# HC32K118 register map
File version: 1.0
CPU: CM0+ r0p1, little endian, no MPU, no FPU, 2 interrupt priority bits
Registers are 32-bit, read-write, reset 0x0 unless marked. A register's access mark holds for its fields unless they carry their own. Offsets are from the block's base; [hi:lo] are bit positions; {n}, {i} and the like mark numbered series; 'fields as' and 'values as' point back to an identical list.

## GPIO
Base 0x40013800
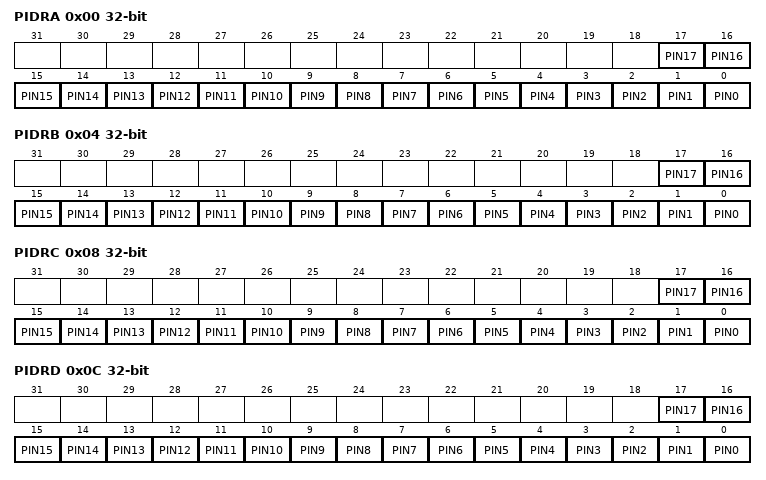
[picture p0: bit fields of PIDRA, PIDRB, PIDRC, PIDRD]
0x00 PIDRA ro (reset mask 0x3CFF)
  [n] PIN{n} (n=0..17)
0x04 PIDRB ro (reset mask 0x3CFF)
  [n] PIN{n} (n=0..17)
0x08 PIDRC ro (reset mask 0x3CFF)
  [n] PIN{n} (n=0..17)
0x0C PIDRD ro (reset mask 0x3CFF)
  [n] PIN{n} (n=0..17)
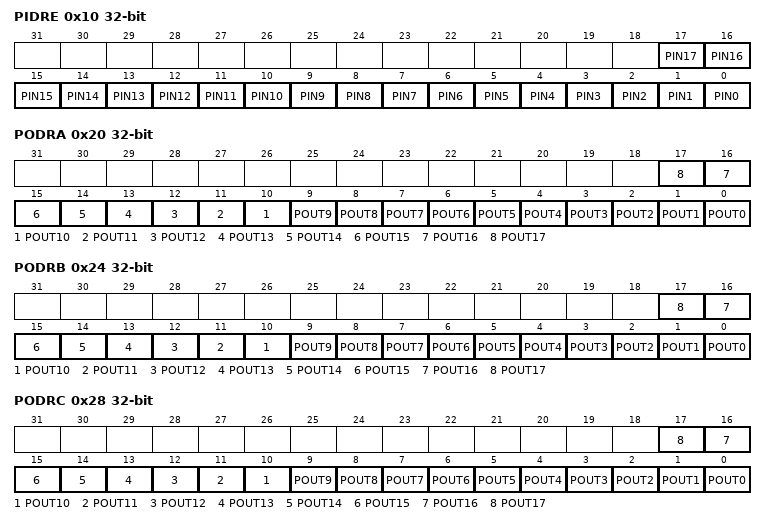
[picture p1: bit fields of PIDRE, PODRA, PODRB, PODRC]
0x10 PIDRE ro (reset mask 0x3CFF)
  [n] PIN{n} (n=0..17)
0x20 PODRA (reset mask 0x3CFF)
  [n] POUT{n} (n=0..17)
0x24 PODRB (reset mask 0x3CFF)
  [n] POUT{n} (n=0..17)
0x28 PODRC (reset mask 0x3CFF)
  [n] POUT{n} (n=0..17)
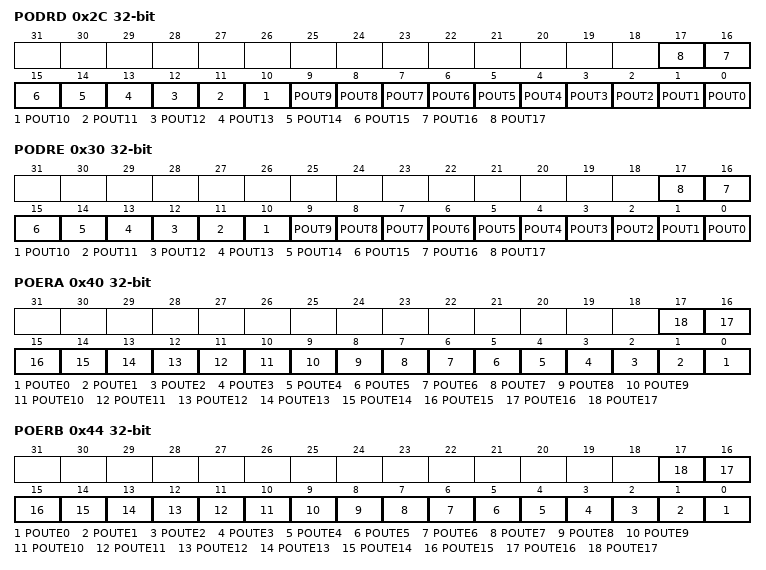
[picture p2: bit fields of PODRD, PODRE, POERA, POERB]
0x2C PODRD (reset mask 0x3CFF)
  [n] POUT{n} (n=0..17)
0x30 PODRE (reset mask 0x3CFF)
  [n] POUT{n} (n=0..17)
0x40 POERA (reset mask 0x3CFF)
  [n] POUTE{n} (n=0..17)
0x44 POERB (reset mask 0x3CFF)
  [n] POUTE{n} (n=0..17)
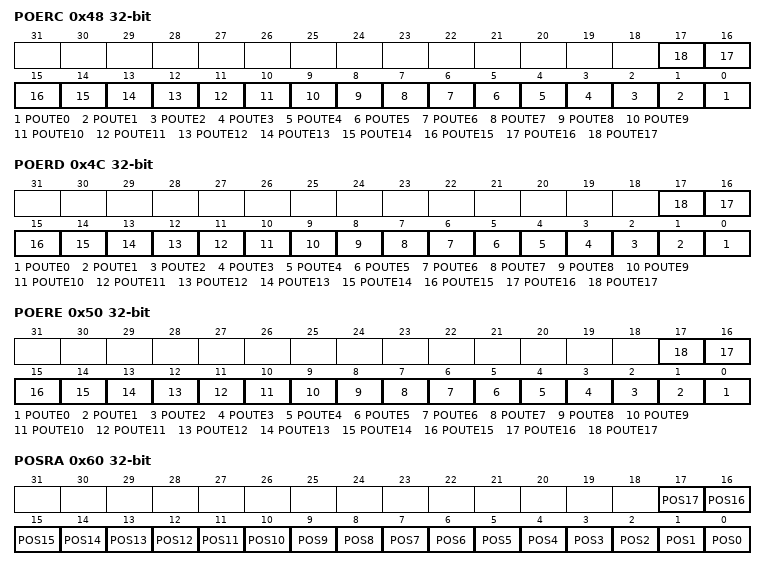
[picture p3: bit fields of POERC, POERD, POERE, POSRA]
0x48 POERC (reset mask 0x3CFF)
  [n] POUTE{n} (n=0..17)
0x4C POERD (reset mask 0x3CFF)
  [n] POUTE{n} (n=0..17)
0x50 POERE (reset mask 0x3CFF)
  [n] POUTE{n} (n=0..17)
0x60 POSRA (reset mask 0x3CFF)
  [n] POS{n} (n=0..17)
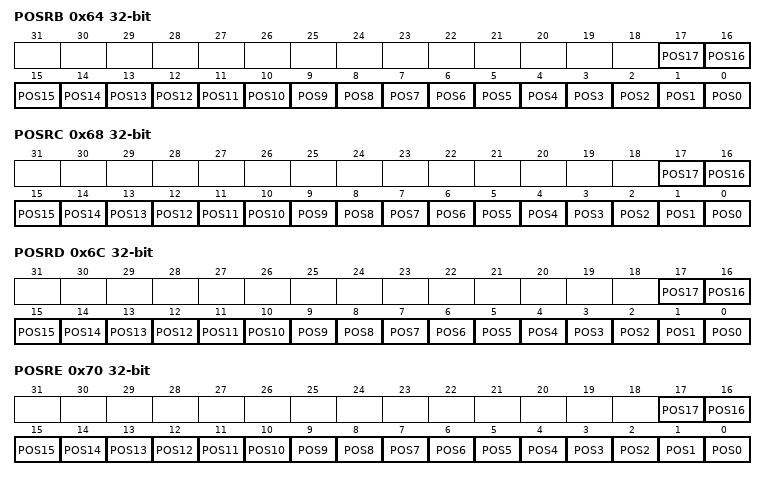
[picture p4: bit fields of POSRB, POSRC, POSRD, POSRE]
0x64 POSRB (reset mask 0x3CFF)
  [n] POS{n} (n=0..17)
0x68 POSRC (reset mask 0x3CFF)
  [n] POS{n} (n=0..17)
0x6C POSRD (reset mask 0x3CFF)
  [n] POS{n} (n=0..17)
0x70 POSRE (reset mask 0x3CFF)
  [n] POS{n} (n=0..17)
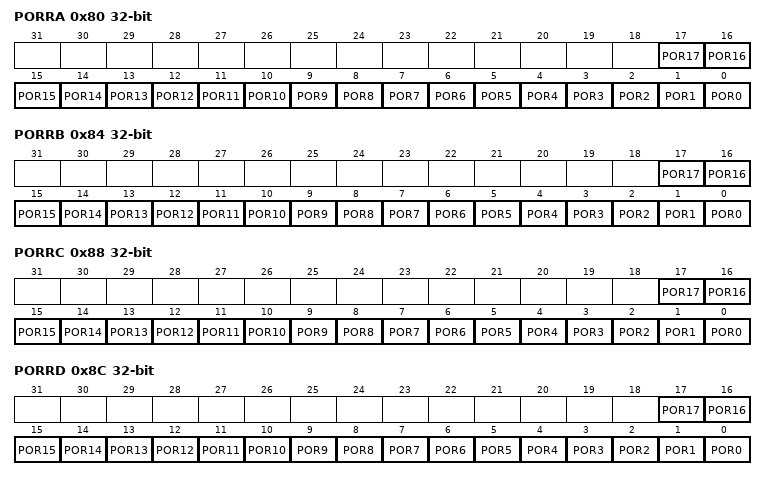
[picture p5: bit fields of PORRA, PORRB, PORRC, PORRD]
0x80 PORRA (reset mask 0x3CFF)
  [n] POR{n} (n=0..17)
0x84 PORRB (reset mask 0x3CFF)
  [n] POR{n} (n=0..17)
0x88 PORRC (reset mask 0x3CFF)
  [n] POR{n} (n=0..17)
0x8C PORRD (reset mask 0x3CFF)
  [n] POR{n} (n=0..17)
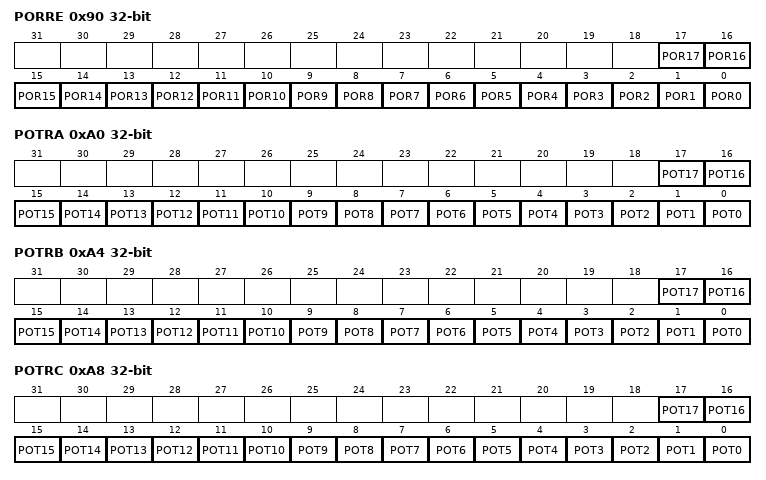
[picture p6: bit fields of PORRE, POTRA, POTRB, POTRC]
0x90 PORRE (reset mask 0x3CFF)
  [n] POR{n} (n=0..17)
0xA0 POTRA (reset mask 0x3CFF)
  [n] POT{n} (n=0..17)
0xA4 POTRB (reset mask 0x3CFF)
  [n] POT{n} (n=0..17)
0xA8 POTRC (reset mask 0x3CFF)
  [n] POT{n} (n=0..17)
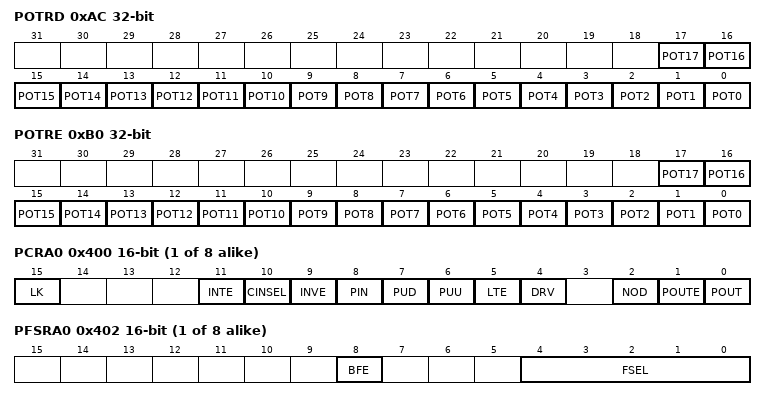
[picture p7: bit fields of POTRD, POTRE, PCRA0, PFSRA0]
0xAC POTRD (reset mask 0x3CFF)
  [n] POT{n} (n=0..17)
0xB0 POTRE (reset mask 0x3CFF)
  [n] POT{n} (n=0..17)
{0x400+4i} PCRA{i} 16-bit (i=0..7)
  [15] LK, [11] INTE, [10] CINSEL, [9] INVE, [8] PIN ro, [7] PUD, [6] PUU, [5] LTE, [4] DRV, [2] NOD, [1] POUTE, [0] POUT
{0x402+4i} PFSRA{i} 16-bit (i=0..7)
  [8] BFE, [4:0] FSEL
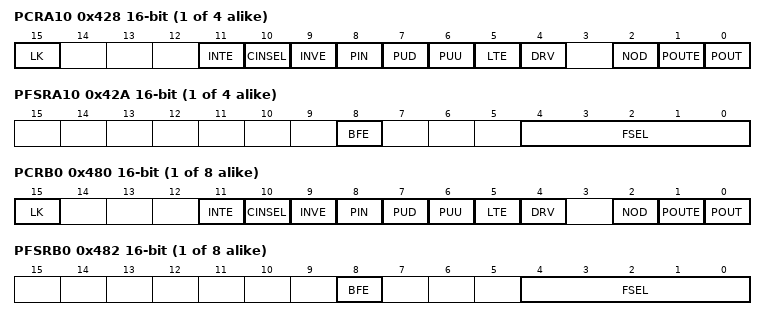
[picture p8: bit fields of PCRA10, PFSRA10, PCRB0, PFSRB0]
{0x400+4i} PCRA{i} 16-bit (i=10..13)
  fields as PCRA0
{0x402+4i} PFSRA{i} 16-bit (i=10..13)
  [8] BFE, [4:0] FSEL
{0x480+4i} PCRB{i} 16-bit (i=0..7)
  fields as PCRA0
{0x482+4i} PFSRB{i} 16-bit (i=0..7)
  [8] BFE, [4:0] FSEL
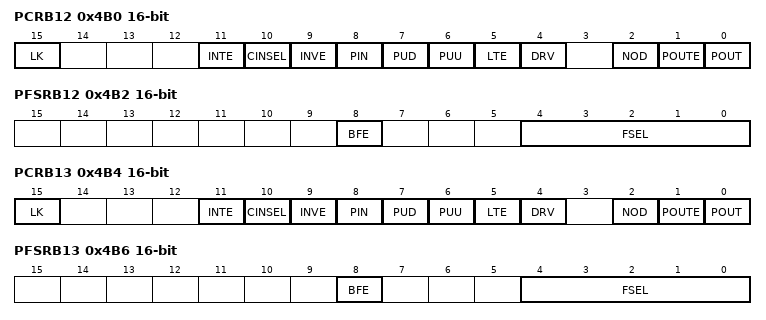
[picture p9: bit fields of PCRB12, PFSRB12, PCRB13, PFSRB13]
0x4B0 PCRB12 16-bit
  fields as PCRA0
0x4B2 PFSRB12 16-bit
  [8] BFE, [4:0] FSEL
0x4B4 PCRB13 16-bit
  fields as PCRA0
0x4B6 PFSRB13 16-bit
  [8] BFE, [4:0] FSEL
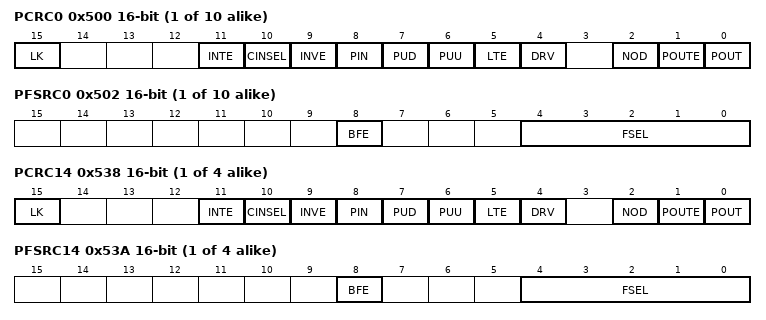
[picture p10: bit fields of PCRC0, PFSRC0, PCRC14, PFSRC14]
{0x500+4i} PCRC{i} 16-bit (i=0..9)
  fields as PCRA0
{0x502+4i} PFSRC{i} 16-bit (i=0..9)
  [8] BFE, [4:0] FSEL
{0x500+4i} PCRC{i} 16-bit (i=14..17)
  fields as PCRA0
{0x502+4i} PFSRC{i} 16-bit (i=14..17)
  [8] BFE, [4:0] FSEL
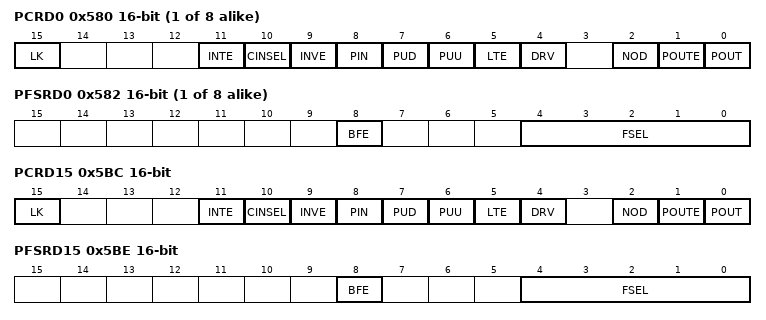
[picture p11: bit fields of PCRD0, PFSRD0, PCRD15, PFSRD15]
{0x580+4i} PCRD{i} 16-bit (i=0..7)
  fields as PCRA0
{0x582+4i} PFSRD{i} 16-bit (i=0..7)
  [8] BFE, [4:0] FSEL
0x5BC PCRD15 16-bit
  fields as PCRA0
0x5BE PFSRD15 16-bit
  [8] BFE, [4:0] FSEL
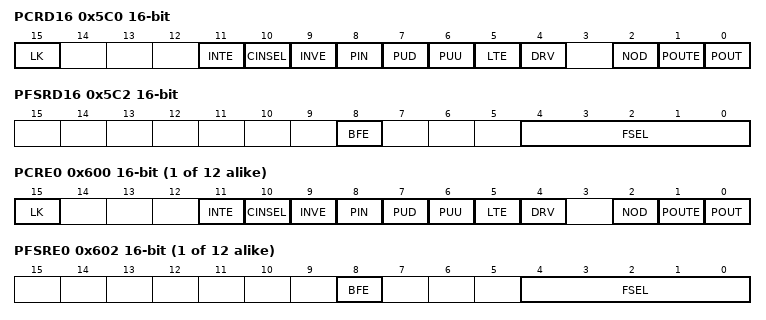
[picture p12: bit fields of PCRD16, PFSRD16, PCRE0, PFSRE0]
0x5C0 PCRD16 16-bit
  fields as PCRA0
0x5C2 PFSRD16 16-bit
  [8] BFE, [4:0] FSEL
{0x600+4i} PCRE{i} 16-bit (i=0..11)
  fields as PCRA0
{0x602+4i} PFSRE{i} 16-bit (i=0..11)
  [8] BFE, [4:0] FSEL
0x700 PSPCR 16-bit reset 0x103
  [1:0] SPFE
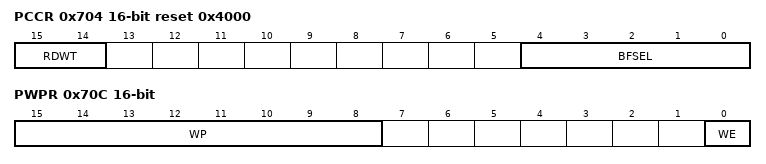
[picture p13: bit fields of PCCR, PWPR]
0x704 PCCR 16-bit reset 0x4000
  [15:14] RDWT, [4:0] BFSEL
0x708 PINAER
  [4:0] PINAE
0x70C PWPR 16-bit
  [15:8] WP wo, [0] WE

## I2C
Base 0x40004800
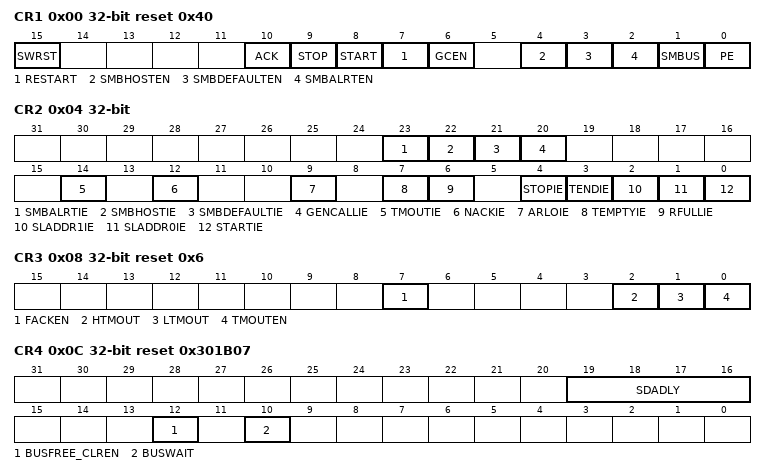
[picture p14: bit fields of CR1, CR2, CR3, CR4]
0x00 CR1 reset 0x40
  [15] SWRST, [10] ACK, [9] STOP, [8] START, [7] RESTART, [6] GCEN, [4] SMBHOSTEN, [3] SMBDEFAULTEN, [2] SMBALRTEN, [1] SMBUS, [0] PE
0x04 CR2
  [23] SMBALRTIE, [22] SMBHOSTIE, [21] SMBDEFAULTIE, [20] GENCALLIE, [14] TMOUTIE, [12] NACKIE, [9] ARLOIE, [7] TEMPTYIE, [6] RFULLIE, [4] STOPIE, [3] TENDIE, [2] SLADDR1IE, [1] SLADDR0IE, [0] STARTIE
0x08 CR3 reset 0x6
  [7] FACKEN, [2] HTMOUT, [1] LTMOUT, [0] TMOUTEN
0x0C CR4 reset 0x301B07
  [19:16] SDADLY, [12] BUSFREE_CLREN, [10] BUSWAIT
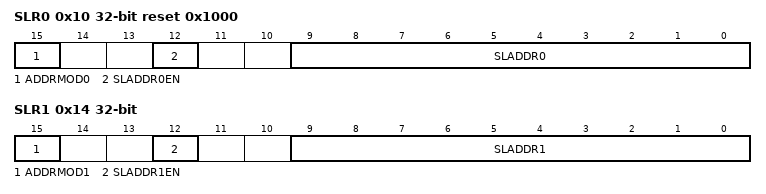
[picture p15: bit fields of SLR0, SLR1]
0x10 SLR0 reset 0x1000
  [15] ADDRMOD0, [12] SLADDR0EN, [9:0] SLADDR0
0x14 SLR1
  [15] ADDRMOD1, [12] SLADDR1EN, [9:0] SLADDR1
0x18 SLTR reset 0xFFFFFFFF
  [31] TOUTHIGH, [30] TOUTLOW
0x1C SR
  [23] SMBALRTF ro, [22] SMBHOSTF ro, [21] SMBDEFAULTF ro, [20] GENCALLF ro, [18] TRA, [17] BUSY ro, [16] MSL, [14] TMOUTF ro, [12] NACKF ro, [10] ACKRF ro, [9] ARLOF ro, [7] TEMPTYF ro, [6] RFULLF ro, [4] STOPF ro, [3] TENDF ro, [2] SLADDR1F ro, [1] SLADDR0F ro, [0] STARTF ro
0x20 CLR wo
  [23] SMBALRTFCLR, [22] SMBHOSTFCLR, [21] SMBDEFAULTFCLR, [20] GENCALLFCLR, [14] TMOUTFCLR, [12] NACKFCLR, [9] ARLOFCLR, [6] RFULLFCLR, [4] STOPFCLR, [3] TENDFCLR, [2] SLADDR1FCLR, [1] SLADDR0FCLR, [0] STARTFCLR
0x24 DTR 8-bit reset 0xFF
0x28 DRR 8-bit ro
0x2C CCR reset 0x1F1F
  [18:16] CKDIV, [12:8] SHIGHW, [4:0] SLOWW
0x30 FLTR reset 0x10
  [5] ANFEN, [4] DNFEN, [1:0] DNF
